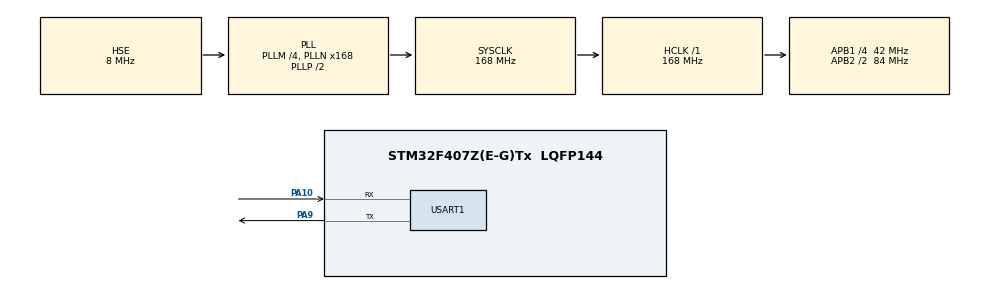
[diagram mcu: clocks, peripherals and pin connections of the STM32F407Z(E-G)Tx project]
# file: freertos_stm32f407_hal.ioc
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Dma.Request0=USART1_RX
Dma.Request1=USART1_TX
Dma.USART1_RX.0.Direction=DMA_PERIPH_TO_MEMORY
Dma.USART1_RX.0.FIFOMode=DMA_FIFOMODE_DISABLE
Dma.USART1_RX.0.Instance=DMA2_Stream2
Dma.USART1_RX.0.MemDataAlignment=DMA_MDATAALIGN_BYTE
Dma.USART1_RX.0.MemInc=DMA_MINC_ENABLE
Dma.USART1_RX.0.Mode=DMA_NORMAL
Dma.USART1_RX.0.PeriphDataAlignment=DMA_PDATAALIGN_BYTE
Dma.USART1_RX.0.PeriphInc=DMA_PINC_DISABLE
Dma.USART1_RX.0.Priority=DMA_PRIORITY_LOW
Dma.USART1_TX.1.Direction=DMA_MEMORY_TO_PERIPH
Dma.USART1_TX.1.FIFOMode=DMA_FIFOMODE_DISABLE
Dma.USART1_TX.1.Instance=DMA2_Stream7
Dma.USART1_TX.1.MemDataAlignment=DMA_MDATAALIGN_BYTE
Dma.USART1_TX.1.MemInc=DMA_MINC_ENABLE
Dma.USART1_TX.1.Mode=DMA_NORMAL
Dma.USART1_TX.1.PeriphDataAlignment=DMA_PDATAALIGN_BYTE
Dma.USART1_TX.1.PeriphInc=DMA_PINC_DISABLE
Dma.USART1_TX.1.Priority=DMA_PRIORITY_LOW
FREERTOS.Tasks01=defaultTask,0,128,StartDefaultTask,Default,NULL,Dynamic,NULL,NULL;myTask02,-3,128,StartTask02,Default,NULL,Dynamic,NULL,NULL
Mcu.Family=STM32F4
Mcu.Name=STM32F407Z(E-G)Tx
Mcu.Package=LQFP144
NVIC.DMA2_Stream2_IRQn=true\:5\:0\:false\:false\:true\:true\:false\:true
NVIC.DMA2_Stream7_IRQn=true\:5\:0\:false\:false\:true\:true\:false\:true
NVIC.PriorityGroup=NVIC_PRIORITYGROUP_4
NVIC.USART1_IRQn=true\:5\:0\:false\:false\:true\:true\:true\:true
PA10.Mode=Asynchronous
PA10.Signal=USART1_RX
PA9.Mode=Asynchronous
PA9.Signal=USART1_TX
PC14-OSC32_IN.Mode=LSE-External-Oscillator
PC14-OSC32_IN.Signal=RCC_OSC32_IN
PC15-OSC32_OUT.Mode=LSE-External-Oscillator
PC15-OSC32_OUT.Signal=RCC_OSC32_OUT
PH0-OSC_IN.Mode=HSE-External-Oscillator
PH0-OSC_IN.Signal=RCC_OSC_IN
PH1-OSC_OUT.Mode=HSE-External-Oscillator
PH1-OSC_OUT.Signal=RCC_OSC_OUT
ProjectManager.HeapSize=0x200
ProjectManager.StackSize=0x400
ProjectManager.TargetToolchain=MDK-ARM V5.32
RCC.48MHZClocksFreq_Value=84000000
RCC.AHBFreq_Value=168000000
RCC.APB1CLKDivider=RCC_HCLK_DIV4
RCC.APB1Freq_Value=42000000
RCC.APB1TimFreq_Value=84000000
RCC.APB2CLKDivider=RCC_HCLK_DIV2
RCC.APB2Freq_Value=84000000
RCC.APB2TimFreq_Value=168000000
RCC.CortexFreq_Value=168000000
RCC.HCLKFreq_Value=168000000
RCC.HSE_VALUE=8000000
RCC.HSI_VALUE=16000000
RCC.PLLM=4
RCC.PLLN=168
RCC.PLLSourceVirtual=RCC_PLLSOURCE_HSE
RCC.SYSCLKFreq_VALUE=168000000
RCC.SYSCLKSource=RCC_SYSCLKSOURCE_PLLCLK
RCC.VCOOutputFreq_Value=336000000
USART1.VirtualMode=VM_ASYNC
VP_FREERTOS_VS_CMSIS_V1.Mode=CMSIS_V1
board=custom

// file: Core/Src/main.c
/* USER CODE BEGIN Header */
/**
  ******************************************************************************
  * @file           : main.c
  * @brief          : Main program body
  ******************************************************************************
  * @attention
  *
  * <h2><center>&copy; Copyright (c) 2022 STMicroelectronics.
  * All rights reserved.</center></h2>
  *
  * This software component is licensed by ST under Ultimate Liberty license
  * SLA0044, the "License"; You may not use this file except in compliance with
  * the License. You may obtain a copy of the License at:
  *                             www.st.com/SLA0044
  *
  ******************************************************************************
  */
/* USER CODE END Header */
#include "main.h"
#include "cmsis_os.h"
#include "dma.h"
#include "usart.h"
#include "gpio.h"

void SystemClock_Config(void);
void MX_FREERTOS_Init(void);

int main(void)
{

  /* MCU Configuration--------------------------------------------------------*/

  /* Reset of all peripherals, Initializes the Flash interface and the Systick. */
  HAL_Init();

  /* Configure the system clock */
  SystemClock_Config();

  /* Initialize all configured peripherals */
  MX_GPIO_Init();
  MX_DMA_Init();
  MX_USART1_UART_Init();
  /* USER CODE BEGIN 2 */
  HAL_UART_Receive_DMA(&huart1, ar_usart1_rx_buffer, MAX_RECEIVE_DATA);
  __HAL_UART_ENABLE_IT(&huart1, UART_IT_IDLE);
  /* USER CODE END 2 */

  /* Call init function for freertos objects (in freertos.c) */
  MX_FREERTOS_Init();
  /* Start scheduler */
  osKernelStart();

  /* We should never get here as control is now taken by the scheduler */
  /* Infinite loop */
  while (1)
  {

  }
}

void SystemClock_Config(void)
{
  RCC_OscInitTypeDef RCC_OscInitStruct = {0};
  RCC_ClkInitTypeDef RCC_ClkInitStruct = {0};

  /** Configure the main internal regulator output voltage
  */
  __HAL_RCC_PWR_CLK_ENABLE();
  __HAL_PWR_VOLTAGESCALING_CONFIG(PWR_REGULATOR_VOLTAGE_SCALE1);
  /** Initializes the RCC Oscillators according to the specified parameters
  * in the RCC_OscInitTypeDef structure.
  */
  RCC_OscInitStruct.OscillatorType = RCC_OSCILLATORTYPE_HSE;
  RCC_OscInitStruct.HSEState = RCC_HSE_ON;
  RCC_OscInitStruct.PLL.PLLState = RCC_PLL_ON;
  RCC_OscInitStruct.PLL.PLLSource = RCC_PLLSOURCE_HSE;
  RCC_OscInitStruct.PLL.PLLM = 4;
  RCC_OscInitStruct.PLL.PLLN = 168;
  RCC_OscInitStruct.PLL.PLLP = RCC_PLLP_DIV2;
  RCC_OscInitStruct.PLL.PLLQ = 4;
  if (HAL_RCC_OscConfig(&RCC_OscInitStruct) != HAL_OK)
  {
    Error_Handler();
  }
  /** Initializes the CPU, AHB and APB buses clocks
  */
  RCC_ClkInitStruct.ClockType = RCC_CLOCKTYPE_HCLK|RCC_CLOCKTYPE_SYSCLK
                              |RCC_CLOCKTYPE_PCLK1|RCC_CLOCKTYPE_PCLK2;
  RCC_ClkInitStruct.SYSCLKSource = RCC_SYSCLKSOURCE_PLLCLK;
  RCC_ClkInitStruct.AHBCLKDivider = RCC_SYSCLK_DIV1;
  RCC_ClkInitStruct.APB1CLKDivider = RCC_HCLK_DIV4;
  RCC_ClkInitStruct.APB2CLKDivider = RCC_HCLK_DIV2;

  if (HAL_RCC_ClockConfig(&RCC_ClkInitStruct, FLASH_LATENCY_5) != HAL_OK)
  {
    Error_Handler();
  }
}

void Error_Handler(void)
{
  __disable_irq();
  while (1)
  {
  }
}

/************************ (C) COPYRIGHT STMicroelectronics *****END OF FILE****/

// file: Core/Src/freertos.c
/* USER CODE BEGIN Header */
/**
  ******************************************************************************
  * File Name          : freertos.c
  * Description        : Code for freertos applications
  ******************************************************************************
  * @attention
  *
  * <h2><center>&copy; Copyright (c) 2022 STMicroelectronics.
  * All rights reserved.</center></h2>
  *
  * This software component is licensed by ST under Ultimate Liberty license
  * SLA0044, the "License"; You may not use this file except in compliance with
  * the License. You may obtain a copy of the License at:
  *                             www.st.com/SLA0044
  *
  ******************************************************************************
  */
/* USER CODE END Header */

#include "FreeRTOS.h"
#include "task.h"
#include "main.h"
#include "cmsis_os.h"

/* USER CODE BEGIN Includes */
#include "usart.h"
/* USER CODE END Includes */

osThreadId defaultTaskHandle;
osThreadId myTask02Handle;

void StartDefaultTask(void const * argument);
void StartTask02(void const * argument);

void MX_FREERTOS_Init(void); /* (MISRA C 2004 rule 8.1) */

/* GetIdleTaskMemory prototype (linked to static allocation support) */
void vApplicationGetIdleTaskMemory( StaticTask_t **ppxIdleTaskTCBBuffer, StackType_t **ppxIdleTaskStackBuffer, uint32_t *pulIdleTaskStackSize );

/* USER CODE BEGIN GET_IDLE_TASK_MEMORY */
static StaticTask_t xIdleTaskTCBBuffer;
static StackType_t xIdleStack[configMINIMAL_STACK_SIZE];

void vApplicationGetIdleTaskMemory( StaticTask_t **ppxIdleTaskTCBBuffer, StackType_t **ppxIdleTaskStackBuffer, uint32_t *pulIdleTaskStackSize )
{
  *ppxIdleTaskTCBBuffer = &xIdleTaskTCBBuffer;
  *ppxIdleTaskStackBuffer = &xIdleStack[0];
  *pulIdleTaskStackSize = configMINIMAL_STACK_SIZE;
  /* place for user code */
}
/* USER CODE END GET_IDLE_TASK_MEMORY */

void MX_FREERTOS_Init(void) {

  /* Create the thread(s) */
  /* definition and creation of defaultTask */
  osThreadDef(defaultTask, StartDefaultTask, osPriorityNormal, 0, 128);
  defaultTaskHandle = osThreadCreate(osThread(defaultTask), NULL);

  /* definition and creation of myTask02 */
  osThreadDef(myTask02, StartTask02, osPriorityIdle, 0, 128);
  myTask02Handle = osThreadCreate(osThread(myTask02), NULL);

}

void StartDefaultTask(void const * argument)
{
  for(;;)
  {
    osDelay(1);
  }
}

void StartTask02(void const * argument)
{
  /* USER CODE BEGIN StartTask02 */
	uint32_t NotifyValue;
  /* Infinite loop */
  for(;;)
  {
    NotifyValue = ulTaskNotifyTake(pdTRUE,portMAX_DELAY);
		if(NotifyValue==1)
		{
				g_usart1_rx_finish=0;
	    	HAL_UART_Transmit_DMA(&huart1,ar_usart1_tx_buffer,g_usart1_rx_len);
		}
		else
		{
			osDelay(10);      //延时10ms，也就是10个时钟节拍
		}
  }
  /* USER CODE END StartTask02 */
}

/************************ (C) COPYRIGHT STMicroelectronics *****END OF FILE****/
